# STM32N657 register map
File version: 1.0
CPU: CM55 r0p1, little endian, no MPU, FPU, vendor SysTick, 8 interrupt priority bits
Registers are 32-bit, read-write, reset 0x0 unless marked. A register's access mark holds for its fields unless they carry their own. Offsets are from the block's base; [hi:lo] are bit positions; {n}, {i} and the like mark numbered series; 'fields as' and 'values as' point back to an identical list.

## MCE1 — Memory cipher engine
Base 0x4802B800
Same registers: MCE2 0x4802BC00, MCE3 0x4802C000, MCE4 0x4802E000, MCE1_S 0x5802B800, MCE2_S 0x5802BC00, MCE3_S 0x5802C000, MCE4_S 0x5802E000
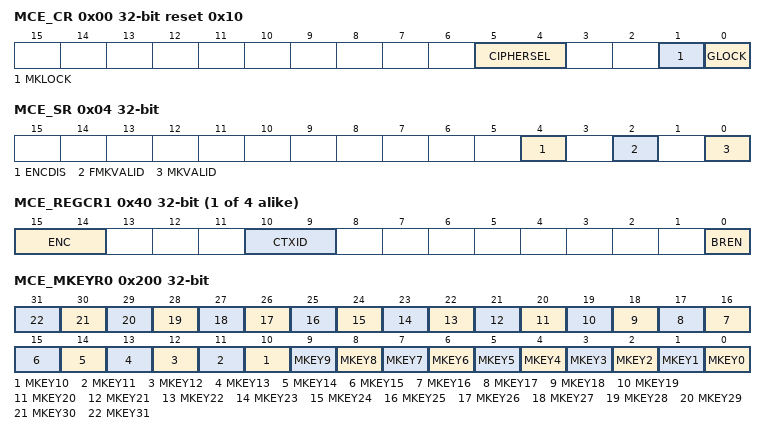
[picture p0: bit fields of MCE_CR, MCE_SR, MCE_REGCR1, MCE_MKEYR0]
0x00 MCE_CR reset 0x10 — MCE configuration register
  [5:4] CIPHERSEL — Cipher selection
    1=AES-128 cipher selected for all encrypted regions; 2=Noekeon cipher selected for all encrypted regions; 3=AES-256 cipher selected for all encrypted regions; 0=No cipher is selected. Any read (resp. write) to an encrypted region with BREN=1 returns zero (resp. is ignored), and illegal access flag IAEF bit is set.
  [1] MKLOCK — Master keys lock
    0=Writes to MCE_MKEYRx and MCE_FMKEYRx registers are allowed; 1=Writes to MCE_MKEYRx and MCE_FMKEYRx registers are ignored until next MCE reset
  [0] GLOCK — Global lock
    0=MCE registers are writable; 1=All writes to MCE registers are ignored, with the exception of MCE_IACR and MCE_IAIER registers
0x04 MCE_SR ro — MCE status register
  [4] ENCDIS — encryption disabled
    0=When ENC bit and BREN are set in MCE_REGCRx all allowed write accesses in region x are encrypted, and all allowed read requests are decrypted; 1=When ENC bit and BREN are set in any MCE_REGCRx all write accesses in region x are ignored, and all read requests return zero. All previously written key material are also erased.
  [2] FMKVALID — Fast master key valid
    0=A valid key has not been written in MCE_FMKEYRx registers, or a valid unlocked fast master key has been erased by hardware (if bit was set before); 1=A valid key has been written in MCE_FMKEYRx registers (write R0 -> R1 -> R2 -> R3 or the reverse)
  [0] MKVALID — Master key valid
    0=A valid key has not been written in MCE_MKEYRx registers, or a valid unlocked master key has been erased by hardware (if bit was set before); 1=A valid key has been written in MCE_MKEYRx registers (write R0 -> R1 -> R2 -> R3 or the reverse)
0x08 MCE_IASR ro — MCE illegal access status register
  [1] IAEF — Illegal access error flag
0x0C MCE_IACR wo — MCE illegal access clear register
  [1] IAEF — Illegal access error flag clear
0x10 MCE_IAIER ro — MCE illegal access interrupt enable register
  [1] IAEIE — Illegal access error interrupt enable
    0=Interrupt generation on illegal access errors is disabled; 1=Interrupt generation when an illegal access error occurs (IAEF=1)
0x24 MCE_IADDR ro — MCE illegal address register
  [31:0] IADD — Illegal address
{0x30+0x10*i} MCE_REGCR{i} (i=1..4) — MCE region {i} configuration register
  [15:14] ENC — Encrypted region
    0=No effects; 1=Stream cipher - All allowed read (resp. write) requests are decrypted (resp. encrypted) using the stream cipher, when CCEN bit is set in MCE_CCzCFGR (where CTXID=z).; 2=Block cipher - All allowed read (resp. write) requests are decrypted (resp. encrypted) using the SCA resistant block cipher. If CTXID=0 and MKVALID=0 bypass mode is selected instead. If CTXID=z and CCEN bit is cleared in MCE_CCzCFGR bypass mode is also selected.; 3=Fast block cipher - All allowed read (resp. write) requests are decrypted (resp. encrypted) using the fast block cipher. If CTXID=0 and FMKVALID=0 bypass mode is selected instead. If CTXID=z and CCEN bit is cleared in MCE_CCzCFGR bypass mode is also selected.
  [10:9] CTXID — Context ID
    0=If ENC=10 (resp. 11) the key stored in MCE_MKEYR (resp. MCE_FMKEYR) registers is used by the block cipher. If ENC=01 bypass mode is selected instead of stream cipher.; 1=If ENC=10 or 11 the key stored in MCE_CC1KEYR is used by the block cipher; 2=If ENC=10 or 11 the key stored in MCE_CC2KEYR is used by the block cipher
  [0] BREN — Base region enable
    0=Region x is disabled. Access control of primary region (privileged or unprivileged, no encryption) applies to any access between this region start and end addresses.; 1=Region x is enable. Access controls and encryption option defined in this region apply to any access between this region start and end addresses.
{0x34+0x10*i} MCE_SADDR{i} (i=1..4) — MCE start address for region {i} register
  [31:12] BADDSTART — Region address start
{0x38+0x10*i} MCE_EADDR{i} reset 0xFFF (i=1..4) — MCE end address for region {i} register
  [31:12] BADDEND — Region address end
0x200 MCE_MKEYR0 wo — .MCE master key 0
  [n] MKEY{n} (n=0..31) — Master key bit {n} (i = 31 to 0)
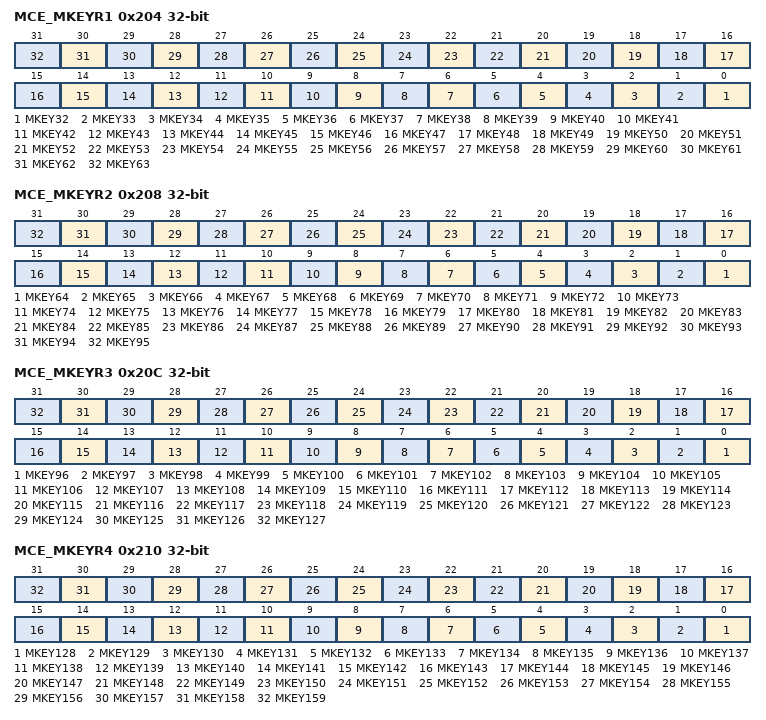
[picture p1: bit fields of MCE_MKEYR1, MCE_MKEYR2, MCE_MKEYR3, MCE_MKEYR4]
0x204 MCE_MKEYR1 wo — .MCE master key 1
  [n-32] MKEY{n} (n=32..63) — Master key bit {n} (i = 31 to 0)
0x208 MCE_MKEYR2 wo — .MCE master key 2
  [n-64] MKEY{n} (n=64..95) — Master key bit {n} (i = 31 to 0)
0x20C MCE_MKEYR3 wo — .MCE master key 3
  [n-96] MKEY{n} (n=96..127) — Master key bit {n} (i = 31 to 0)
0x210 MCE_MKEYR4 wo — .MCE master key 4
  [n-128] MKEY{n} (n=128..159) — Master key bit {n} (i = 31 to 0)
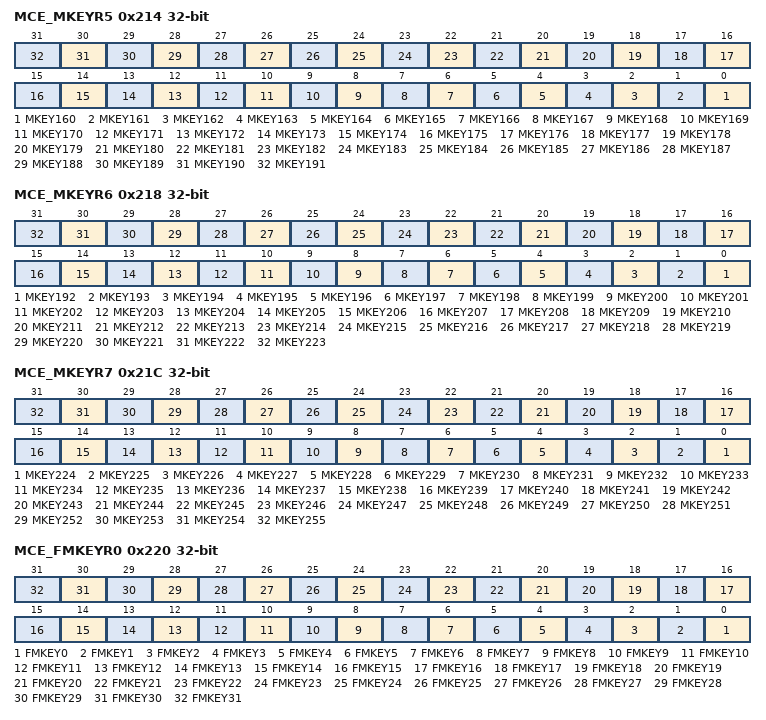
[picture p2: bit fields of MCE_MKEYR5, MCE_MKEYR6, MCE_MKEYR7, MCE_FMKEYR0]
0x214 MCE_MKEYR5 wo — .MCE master key 5
  [n-160] MKEY{n} (n=160..191) — Master key bit {n} (i = 31 to 0)
0x218 MCE_MKEYR6 wo — .MCE master key 6
  [n-192] MKEY{n} (n=192..223) — Master key bit {n} (i = 31 to 0)
0x21C MCE_MKEYR7 wo — .MCE master key 7
  [n-224] MKEY{n} (n=224..255) — Master key bit {n} (i = 31 to 0)
0x220 MCE_FMKEYR0 wo — MCE fast master key 0
  [n] FMKEY{n} (n=0..31) — Fast master key bit {n} (i = 31 to 0)
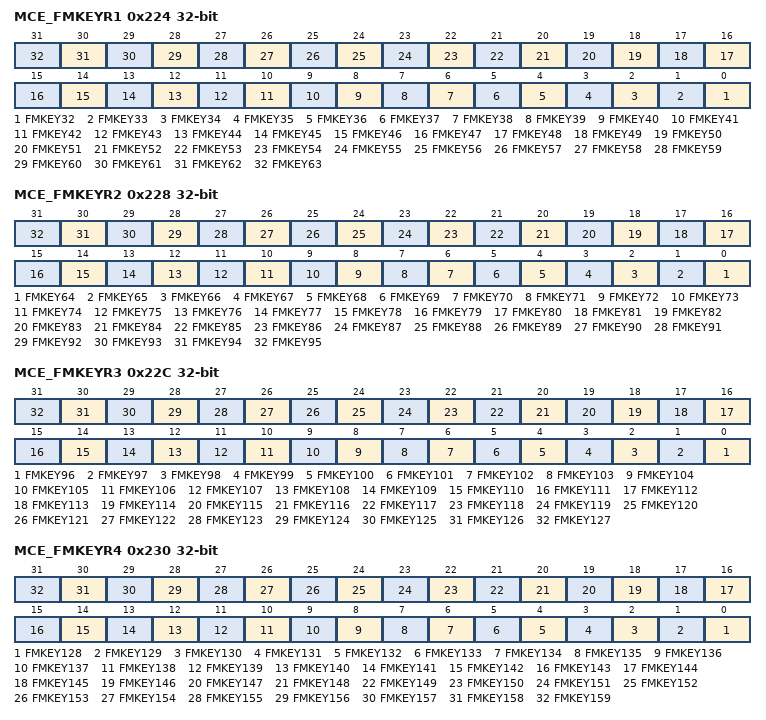
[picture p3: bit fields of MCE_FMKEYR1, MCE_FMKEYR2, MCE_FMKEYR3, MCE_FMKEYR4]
0x224 MCE_FMKEYR1 wo — MCE fast master key 1
  [n-32] FMKEY{n} (n=32..63) — Fast master key bit {n} (i = 31 to 0)
0x228 MCE_FMKEYR2 wo — MCE fast master key 2
  [n-64] FMKEY{n} (n=64..95) — Fast master key bit {n} (i = 31 to 0)
0x22C MCE_FMKEYR3 wo — MCE fast master key 3
  [n-96] FMKEY{n} (n=96..127) — Fast master key bit {n} (i = 31 to 0)
0x230 MCE_FMKEYR4 wo — MCE fast master key 4
  [n-128] FMKEY{n} (n=128..159) — Fast master key bit {n} (i = 31 to 0)
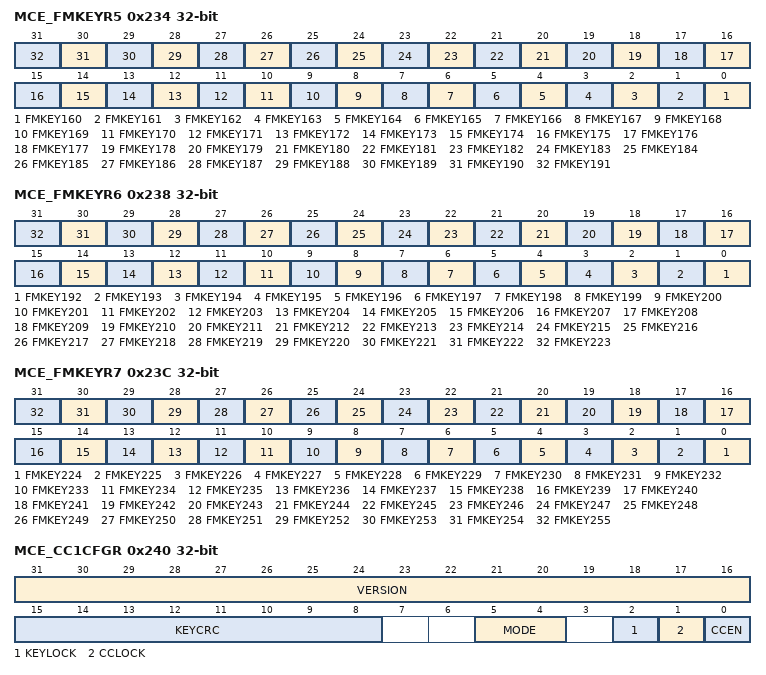
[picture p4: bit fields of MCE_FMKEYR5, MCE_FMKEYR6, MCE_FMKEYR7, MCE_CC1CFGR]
0x234 MCE_FMKEYR5 wo — MCE fast master key 5
  [n-160] FMKEY{n} (n=160..191) — Fast master key bit {n} (i = 31 to 0)
0x238 MCE_FMKEYR6 wo — MCE fast master key 6
  [n-192] FMKEY{n} (n=192..223) — Fast master key bit {n} (i = 31 to 0)
0x23C MCE_FMKEYR7 wo — MCE fast master key 7
  [n-224] FMKEY{n} (n=224..255) — Fast master key bit {n} (i = 31 to 0)
0x240 MCE_CC1CFGR access per field — MCE cipher context 1 configuration register
  [31:16] VERSION rw
  [15:8] KEYCRC ro
  [5:4] MODE rw — Authorized cipher mode
    2=Block cipher is allowed with this cipher context; 3=Fast block cipher is allowed with this cipher context
  [2] KEYLOCK rw
    0=Writes to MCE_CCzKEYR registers are allowed; 1=Writes to MCE_CCzKEYR registers are ignored until next MCE reset. KEYCRC bitfield value does not change.
  [1] CCLOCK rw — Cipher context lock
    0=Writes to MCE_CCzCFGR and MCE_CCzNR registers are allowed; 1=Writes to MCE_CCzCFGR and MCE_CCzNR registers are ignored until next MCE reset
  [0] CCEN rw — Cipher context enable
    0=If an enabled region selects CTXID=z bypass mode is selected by MCE; 1=If an enabled region selects CTXID=z with ENC=01 MCE selects with the stream cipher the information stored in MCE_CCzCFGR, MCE_CCzNR and MCE_CCzKEYR. If the enabled region selects ENC=10 or 11 instead MCE selects with the block cipher the key information stored in MCE_CCzKEYR. When CCEN is set and MODE[1:0] bits do not allow the configuration written in ENC[1:0] bits (see MODE bitfield) reads return zero and writes are ignored.
0x244 MCE_CC1NR0 — MCE cipher context 1 nonce register 0
  [31:0] SCNONCE — Stream cipher nonce, bits [31:0]
0x248 MCE_CC1NR1 — MCE cipher context 1 nonce register 1
  [31:0] SCNONCE — Stream cipher nonce, bits [63:32]
{0x24C+4i} MCE_CC1KEYR{i} wo (i=0..3) — MCE cipher context 1 key register {i}
  [31:0] KEY — cipher key, bits [{32i+31}:{32i}]
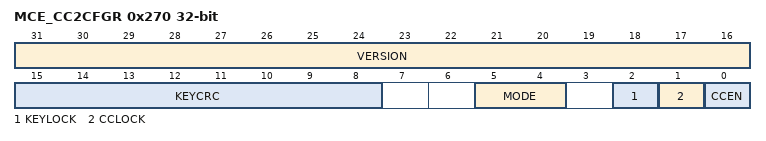
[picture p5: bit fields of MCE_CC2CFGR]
0x270 MCE_CC2CFGR access per field — MCE cipher context 2 configuration register
  fields as MCE_CC1CFGR
0x274 MCE_CC2NR0 — MCE cipher context 2 nonce register 0
  [31:0] SCNONCE — Stream cipher nonce, bits [31:0]
0x278 MCE_CC2NR1 — MCE cipher context 2 nonce register 1
  [31:0] SCNONCE — Stream cipher nonce, bits [63:32]
{0x27C+4i} MCE_CC2KEYR{i} wo (i=0..3) — MCE cipher context 2 key register {i}
  [31:0] KEY — cipher key, bits [{32i+31}:{32i}]
